# R40 register map
Vendor: Allwinner; Series: R40; File version: 0.1
CPU: CA7 0, little endian, MPU, FPU, double-precision FPU, 0 interrupt priority bits
Registers are 32-bit, read-write, reset 0x0 unless marked. A register's access mark holds for its fields unless they carry their own. Offsets are from the block's base; [hi:lo] are bit positions; {n}, {i} and the like mark numbered series; 'fields as' and 'values as' point back to an identical list; <NAME> marks a mode.

## Audio_Codec
Base 0x01C22C00
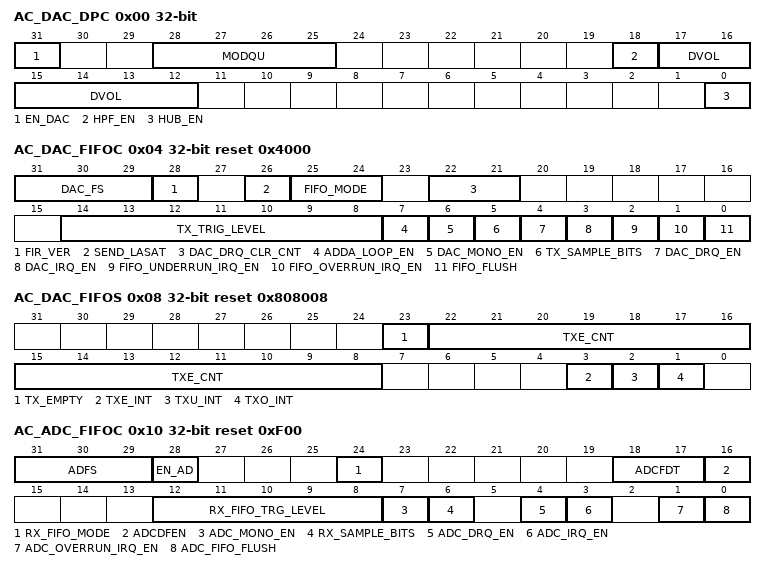
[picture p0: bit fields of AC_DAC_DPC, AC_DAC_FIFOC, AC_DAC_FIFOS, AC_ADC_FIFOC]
0x00 AC_DAC_DPC — DAC Digital Part Control Register
  [31] EN_DAC — DAC Digital Part Enable 0 : Disable 1 : Enable
  [28:25] MODQU — Internal DAC Quantization Levels Levels=[7*(21+MODQU[3:0])]/128 Default levels=7*21/128=1.15
  [18] HPF_EN — High Pass Filter Enable 0: Disable 1: Enable
    0=Disable; 1=Enable
  [17:12] DVOL — Digital Volume Control DVC, ATT=DVC[5:0]*(-1.16Db) 64 steps, -1.16Db/step
  [0] HUB_EN — Audio Hub Enable 0:Disable 1:Enable
0x04 AC_DAC_FIFOC reset 0x4000 — DAC FIFO Control Register
  [31:29] DAC_FS — Sample Rate Of DAC 000: 48KHz 010: 24KHz 100: 12KHz 110: 192KHz 001: 32KHz 011: 16KHz 101: 8KHz 111: 96KHz 44.1KHz/22.05KHz/11.025KHz can be supported by Audio PLL Configure Bit
    0=_48KHz; 2=_24KHz; 4=_12KHz; 6=_192KHz; 1=_32KHz; 3=_16KHz; 5=_8KHz; 7=96KHz 44.1KHz/22.05KHz/11.025KHz can be supported by Audio PLL Configure Bit
  [28] FIR_VER — FIR Version 0: 64-Tap FIR 1: 32-Tap FIR
    0=_64_minus_Tap (64-Tap FIR); 1=_32_minus_Tap (32-Tap FIR)
  [26] SEND_LASAT — Audio sample select when TX FIFO under run 0: Sending zero 1: Sending last audio sample
    0=Sending_zero; 1=Sending last audio sample
  [25:24] FIFO_MODE — For 24-bits transmitted audio sample 00/10: FIFO_I[23:0] = {TXDATA[31:8]} 01/11: Reserved For 16-bits transmitted audio sample: 00/10: FIFO_I*23:0+ = ,TXDATA*31:16+, 8`b0- 01/11: FIFO_I*23:0+ = ,TXDATA*15:0+, 8`b0-
  [22:21] DAC_DRQ_CLR_CNT — When TX FIFO Available Room Less Than Or Equal N, DRQ Request Will Be De-Asserted. N Is Defined Here: 00: IRQ/DRQ De-Asserted When WLEVEL > TXTL 01: 4 10: 8 11: 16
    0=IRQ_slash_DRQ (IRQ/DRQ De-Asserted When WLEVEL > TXTL); 1=_4; 2=_8; 3=_16
  [14:8] TX_TRIG_LEVEL — TX FIFO Empty Trigger Level (TXTL[12:0]) Interrupt and DMA request trigger level for TX FIFO normal condition. IRQ/DRQ Generated when WLEVEL <= TXTL Notes: 1. WLEVEL represents the number of valid samples in the TX FIFO 2. Only TXTL[6:0] valid when TXMODE = 0
  [7] ADDA_LOOP_EN — ADDA Loop Enable 0: Disable 1: Enable
    0=Disable; 1=Enable
  [6] DAC_MONO_EN — DAC Mono Enable 0: Stereo, 64 Levels FIFO 1: Mono, 128 Levels FIFO When Enabled, L & R Channel Send Same Data
    0=Stereo, 64 Levels FIFO; 1=Mono, 128 Levels FIFO When Enabled, L & R Channel Send Same Data
  [5] TX_SAMPLE_BITS — Transmitting Audio Sample Resolution 0: 16 bits 1: 24 bits
    0=_16_bits; 1=_24_bits
  [4] DAC_DRQ_EN — DAC FIFO Empty DRQ Enable 0: Disable 1: Enable
    0=Disable; 1=Enable
  [3] DAC_IRQ_EN — DAC FIFO Empty IRQ Enable 0: Disable 1: Enable
    0=Disable; 1=Enable
  [2] FIFO_UNDERRUN_IRQ_EN — DAC FIFO Under Run IRQ Enable 0: Disable 1: Enable
    0=Disable; 1=Enable
  [1] FIFO_OVERRUN_IRQ_EN — DAC FIFO Over Run IRQ Enable 0: Disable 1: Enable
    0=Disable; 1=Enable
  [0] FIFO_FLUSH write-1-clears — DAC FIFO Flush Write `1` to flush TX FIFO, Self clear to `0`
0x08 AC_DAC_FIFOS reset 0x808008 — DAC FIFO Status Register
  [23] TX_EMPTY ro — TX FIFO Empty 0: No room for new sample in TX FIFO 1: More than one room for new sample in TX FIFO (>= 1 word)
    0=No room for new sample in TX FIFO; 1=More than one room for new sample in TX FIFO (>= 1 word)
  [22:8] TXE_CNT ro — TX FIFO Empty Space Word Counter
  [3] TXE_INT write-1-clears — TX FIFO Empty Pending Interrupt 0: No Pending IRQ 1: FIFO Empty Pending Interrupt Write `1` to clear this interrupt or automatically clear if interrupt condition fails
    0=No Pending IRQ; 1=FIFO (FIFO Empty Pending Interrupt Write `1` to clear this interrupt or automatically clear if interrupt condition fails)
  [2] TXU_INT write-1-clears — TX FIFO Under run Pending Interrupt 0: No Pending Interrupt 1: FIFO Under run Pending Interrupt Write `1` to clear this interrupt
    0=No Pending Interrupt; 1=FIFO (FIFO Under run Pending Interrupt Write `1` to clear this interrupt)
  [1] TXO_INT write-1-clears — TX FIFO Overrun Pending Interrupt 0: No Pending Interrupt 1: FIFO Overrun Pending Interrupt Write `1` to clear this interrupt
    0=No Pending Interrupt; 1=FIFO (FIFO Overrun Pending Interrupt Write `1` to clear this interrupt)
0x10 AC_ADC_FIFOC reset 0xF00 — ADC FIFO Control Register
  [31:29] ADFS — Sample Rate of ADC 000: 48KHz 010: 24KHz 100: 12KHz 110: Reserved 001: 32KHz 011: 16KHz 101: 8KHz 111: Reserved 44.1KHz/22.05KHz/11.025KHz can be supported by Audio PLL Configure Bit
    0=_48KHz; 2=_24KHz; 4=_12KHz; 1=_32KHz; 3=_16KHz; 5=_8KHz
  [28] EN_AD — ADC Digital Part Enable 0: Disable 1: Enable
    0=Disable; 1=Enable
  [24] RX_FIFO_MODE — RX FIFO Output Mode (Mode 0, 1) 0: Expanding `0` at LSB of TX FIFO register 1: Expanding received sample sign bit at MSB of TX FIFO register For 24-bits received audio sample: Mode 0: RXDATA[31:0+ = ,FIFO_O*23:0+, 8`h0- Mode 1: Reserved For 16-bits received audio sample: Mode 0: RXDATA*31:0+ = ,FIFO_O*23:8+, 16`h0- Mode 1: RXDATA[31:0] = {16{FIFO_O[23]}, FIFO_O[23:8]}
    0=Expanding `0` at LSB of TX FIFO register; 1=Expanding received sample sign bit at MSB of TX FIFO register For 24-bits received audio sample: Mode 0: RXDATA[31:0+ = ,FIFO_O*23:0+, 8`h0- Mode 1: Reserved For 16-bits received audio sample: Mode 0: RXDATA*31:0+ = ,FIFO_O*23:8+, 16`h0- Mode 1: RXDATA[31:0] = {16{FIFO_O[23]}, FIFO_O[23:8]}
  [18:17] ADCFDT — ADC FIFO Delay Time for writing Data after EN_AD 00:5ms 01:10ms 10:20ms 11:30ms
  [16] ADCDFEN — ADC FIFO Delay Function for writing Data after EN_AD 0: Disable 1: Enable
    0=Disable; 1=Enable
  [12:8] RX_FIFO_TRG_LEVEL — RX FIFO Trigger Level (RXTL[4:0]) Interrupt and DMA request trigger level for RX FIFO normal condition IRQ/DRQ Generated when WLEVEL > RXTL[4:0] Notes: WLEVEL represents the number of valid samples in the RX FIFO
  [7] ADC_MONO_EN — ADC Mono Enable 0: Stereo, 16 levels FIFO 1: mono, 32 levels FIFO When set to `1`, Only left channel samples are recorded
    0=Stereo, 16 levels FIFO; 1=mono, 32 levels FIFO When set to `1`, Only left channel samples are recorded
  [6] RX_SAMPLE_BITS — Receiving Audio Sample Resolution 0: 16 bit 1: 24 bit
    0=_16_bit; 1=_24_bit
  [4] ADC_DRQ_EN — ADC FIFO Data Available DRQ Enable 0: Disable 1: Enable
    0=Disable; 1=Enable
  [3] ADC_IRQ_EN — ADC FIFO Data Available IRQ Enable 0: Disable 1: Enable
    0=Disable; 1=Enable
  [1] ADC_OVERRUN_IRQ_EN — ADC FIFO Over Run IRQ Enable 0: Disable 1: Enable
    0=Disable; 1=Enable
  [0] ADC_FIFO_FLUSH write-1-clears — ADC FIFO Flush Write `1` to flush TX FIFO, self clear to `0`
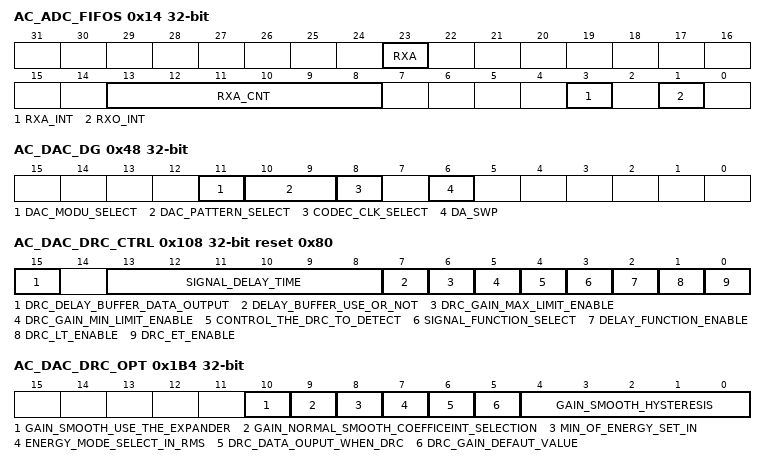
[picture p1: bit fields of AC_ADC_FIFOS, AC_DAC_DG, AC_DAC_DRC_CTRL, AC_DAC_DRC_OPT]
0x14 AC_ADC_FIFOS — ADC FIFO Status Register
  [23] RXA ro — RX FIFO Available 0: No available data in RX FIFO 1: More than one sample in RX FIFO (>= 1 word)
    0=No available data in RX FIFO; 1=More than one sample in RX FIFO (>= 1 word)
  [13:8] RXA_CNT ro — RX FIFO Available Sample Word Counter
  [3] RXA_INT write-1-clears — RX FIFO Data Available Pending Interrupt 0: No Pending IRQ 1: Data Available Pending IRQ Write `1` to clear this interrupt or automatically clear if interrupt condition fails
    0=No Pending IRQ; 1=Data Available Pending IRQ Write `1` to clear this interrupt or automatically clear if interrupt condition fails
  [1] RXO_INT write-1-clears — RX FIFO Overrun Pending Interrupt 0: No Pending IRQ 1: FIFO Overrun Pending IRQ Write `1` to clear this interrupt
    0=No Pending IRQ; 1=FIFO (FIFO Overrun Pending IRQ Write `1` to clear this interrupt)
0x18 AC_ADC_RXDATA — ADC RX Data Register
  [31:0] RX_DATA ro — RX Sample Host can get one sample by reading this register. The left channel sample data is first and then the right channel sample.
0x20 AC_DAC_TXDATA — DAC TX Data Register
  [31:0] TX_DATA wo — Transmitting left, right channel sample data should be written this register one by one. The left channel sample data is first and then the right channel sample.
0x40 AC_DAC_CNT — DAC TX FIFO Counter Register
  [31:0] TX_CNT — TX Sample Counter The audio sample number of sending into TXFIFO. When one sample is put into TXFIFO by DMA or by host IO, the TX sample counter register increases by one. The TX sample counter register can be set to any initial valve at any time. After been updated by the initial value, the counter register should count on base of this initial value. Note: It is used for Audio/ Video Synchronization
0x44 AC_ADC_CNT — ADC RX FIFO Counter Register
  [31:0] RX_CNT — RX Sample Counter The audio sample number of writing into RXFIFO. When one sample is written by Digital Audio Engine, the RX sample counter register increases by one. The RX sample counter register can be set to any initial valve at any time. After been updated by the initial value, the counter register should count on base of this initial value Note: It is used for Audio/ Video Synchronization
0x48 AC_DAC_DG — DAC Debug Register
  [11] DAC_MODU_SELECT — DAC Modulator Debug 0: DAC Modulator Normal Mode 1: DAC Modulator Debug Mode
    0=DAC Modulator Normal Mode; 1=DAC Modulator Debug Mode
  [10:9] DAC_PATTERN_SELECT — DAC Pattern Select 00: Normal (Audio Sample from TX FIFO) 01: -6 dB Sin wave 10: -60 dB Sin wave 11: Silent wave
    0=Normal (Audio Sample from TX FIFO); 1=_minus_6_dB (-6 dB Sin wave); 2=_minus_60_dB (-60 dB Sin wave); 3=Silent wave
  [8] CODEC_CLK_SELECT — CODEC Clock Source Select 0: CODEC Clock from PLL 1: CODEC Clock from OSC (for Debug)
    0=CODEC_Clock_from_PLL; 1=CODEC Clock from OSC (for Debug)
  [6] DA_SWP — DAC output channel swap enable 0: Disable 1: Enable
    0=Disable; 1=Enable
0x4C AC_ADC_DG — ADC Debug Register
  [24] AD_SWP — ADC Output Channel Swap Enable (for digital filter) 0: Disable 1: Enable
    0=Disable; 1=Enable
0x100 AC_DAC_DRC_HHPFC reset 0xFF — DAC DRC High HPF Coef Register
  [10:0] HPF — coefficient setting and the data is 3.24 format.
0x104 AC_DAC_DRC_LHPFC reset 0xFAC1 — DAC DRC Low HPF Coef Register
  [15:0] HPF — coefficient setting and the data is 3.24 format.
0x108 AC_DAC_DRC_CTRL reset 0x80 — DAC DRC Control Register
  [15] DRC_DELAY_BUFFER_DATA_OUTPUT ro — DRC delay buffer data output state when drc delay function is enble and the drc funciton disable. After disable drc function and this bit go to 0, the user should write the drc delay function bit to 0. 0 : Not complete 1 : Complete
  [13:8] SIGNAL_DELAY_TIME — Signal delay time setting 6'h00 : (8x1)fs 6'h01 : (8x2)fs 6'h02 : (8x3)fs ---------------------------------------- 6'h2e : (8*47)fs 6'h2f : (8*48)fs 6'h30 -- 6'h3f : (8*48)fs Delay time = 8*(n+1)fs, n<6'h30; When the delay function is disable, the signal delay time is unused.
  [7] DELAY_BUFFER_USE_OR_NOT — The delay buffer use or not when the drc disable and the drc buffer data output completely 0 : Don't use the buffer 1 : Use the buffer
  [6] DRC_GAIN_MAX_LIMIT_ENABLE — DRC gain max limit enable 0 : Disable 1 : Enable
  [5] DRC_GAIN_MIN_LIMIT_ENABLE — DRC gain min limit enable. when this fuction enable, it will overwrite the noise detect funciton. 0 : Disable 1 : Enable
  [4] CONTROL_THE_DRC_TO_DETECT — Control the drc to detect noise when ET enable 0 : Disable 1 : Enable
  [3] SIGNAL_FUNCTION_SELECT — Signal function Select 0 : RMS filter 1 : Peak filter When Signal function Select Peak filter, the RMS parameter is unused. (AC_DRC_LRMSHAT / AC_DRC_LRMSLAT / AC_DRC_LRMSHAT / AC_DRC_LRMSLAT) When Signal function Select RMS filter, the Peak filter parameter is unused.(AC_DRC_LPFHAT / AC_DRC_LPFLAT / AC_DRC_RPFHAT / AC_DRC_RPFLAT / AC_DRC_LPFHRT / AC_DRC_LPFLRT / AC_DRC_RPFHRT / AC_DRC_RPFLRT)
  [2] DELAY_FUNCTION_ENABLE — Delay function enable 0 : Disable 1 : Enable When the Delay function enable is disabled, the Signal delay time is unused.
  [1] DRC_LT_ENABLE — DRC LT enable 0 : Disable 1 : Enable When the DRC LT is disabled the LT, Kl and OPL parameter is unused.
  [0] DRC_ET_ENABLE — DRC ET enable 0 : Disable 1 : Enable When the DRC ET is disabled the ET, Ke and OPE parameter is unused.
0x10C AC_DAC_DRC_LPFHAT reset 0xB — DAC DRC Left Peak Filter High Attack Time Coef Register
  [10:0] LEFT_PEAK_FILTER_ATTACK_TIME — The left peak filter attack time parameter setting, which determine by the equation that AT = 1-exp(-2.2Ts/ta). The format is 3.24. (1ms)
0x110 AC_DAC_DRC_LPFLAT reset 0x77BF — DAC DRC Left Peak Filter Low Attack Time Coef Register
  [15:0] LEFT_PEAK_FILTER_ATTACK_TIME — The left peak filter attack time parameter setting, which determine by the equation that AT = 1-exp(-2.2Ts/ta). The format is 3.24. (1ms)
0x114 AC_DAC_DRC_RPFHAT reset 0xB — DAC DRC Right Peak Filter High Attack Time Coef Register
  fields as AC_DAC_DRC_LPFHAT
0x118 AC_DAC_DRC_RPFLAT reset 0x77BF — DAC DRC Peak Filter Low Attack Time Coef Register
  fields as AC_DAC_DRC_LPFLAT
0x11C AC_DAC_DRC_LPFHRT reset 0xFF — DAC DRC Left Peak Filter High Release Time Coef Register
  [10:0] LEFT_PEAK_FILTER_RELEASE_TIME — The left peak filter release time parameter setting, which determine by the equation that RT = exp(-2.2Ts/tr). The format is 3.24. (100ms)
0x120 AC_DAC_DRC_LPFLRT reset 0xE1F8 — DAC DRC Left Peak Filter Low Release Time Coef Register
  [15:0] LEFT_PEAK_FILTER_RELEASE_TIME — The left peak filter release time parameter setting, which determine by the equation that RT = exp(-2.2Ts/tr). The format is 3.24. (100ms)
0x124 AC_DAC_DRC_RPFHRT reset 0xFF — DAC DRC Right Peak Filter High Release Time Coef Register
  [10:0] LEFT_PEAK_FILTER_ATTACK_TIME — The left peak filter attack time parameter setting, which determine by the equation that RT = exp(-2.2Ts/tr). The format is 3.24. (100ms)
0x128 AC_DAC_DRC_RPFLRT reset 0xE1F8 — DAC DRC Right Peak Filter Low Release Time Coef Register
  [15:0] LEFT_PEAK_FILTER_RELEASE_TIME — The left peak filter release time parameter setting, which determine by the equation that AT = exp(-2.2Ts/tr). The format is 3.24. (100ms)
0x12C AC_DAC_DRC_LRMSHAT reset 0x1 — DAC DRC Left RMS Filter High Coef Register
  [10:0] LEFT_RMS_FILTER_AVERAGE_TIME — The left RMS filter average time parameter setting, which determine by the equation that AT = 1-exp(-2.2Ts/tav). The format is 3.24. (10ms)
0x130 AC_DAC_DRC_LRMSLAT reset 0x2BAF — DAC DRC Left RMS Filter Low Coef Register
  [15:0] LEFT_RMS_FILTER_AVERAGE_TIME — The left RMS filter average time parameter setting, which determine by the equation that AT = 1-exp(-2.2Ts/tav). The format is 3.24. (10ms)
0x134 AC_DAC_DRC_RRMSHAT reset 0x1 — DAC DRC Right RMS Filter High Coef Register
  [10:0] RIGHT_RMS_FILTER_AVERAGE_TIME — The right RMS filter average time parameter setting, which determine by the equation that AT = 1-exp(-2.2Ts/tav). The format is 3.24. (10ms)
0x138 AC_DAC_DRC_RRMSLAT reset 0x2BAF — DAC DRC Right RMS Filter Low Coef Register
  [15:0] RIGHT_RMS_FILTER_AVERAGE_TIME — The right RMS filter average time parameter setting, which determine by the equation that AT = 1-exp(-2.2Ts/tav). The format is 3.24. (10ms)
0x13C AC_DAC_DRC_HCT reset 0x6A4 — DAC DRC Compressor Theshold High Setting Register
  [15:0] COMPRESSOR_THRESHOLD — The compressor threshold setting, which set by the equation that CTin = -CT/6.0206. The format is 8.24 (-40dB)
0x140 AC_DAC_DRC_LCT reset 0xD3C0 — DAC DRC Compressor Slope High Setting Register
  fields as AC_DAC_DRC_HCT
0x144 AC_DAC_DRC_HKC reset 0x80 — DAC DRC Compressor Slope High Setting Register
  [13:0] COMPRESSOR_SLOPE — The slope of the compressor which determine by the equation that Kc = 1/R, there, R is the ratio of the compressor, which always is interger. The format is 6.24. (2 : 1)
0x148 AC_DAC_DRC_LKC — DAC DRC Compressor Slope Low Setting Register
  [15:0] COMPRESSOR_SLOPE — The slope of the compressor which determine by the equation that Kc = 1/R, there, R is the ratio of the compressor, which always is interger. The format is 6.24. (2 : 1)
0x14C AC_DAC_DRC_HOPC reset 0xF95B — DAC DRC Compressor High Output at Compressor Threshold Register
  [15:0] COMPRESSOR_OUTPUT — The output of the compressor which determine by the equation -OPC/6.0206 The format is 8.24 (-40dB)
0x150 AC_DAC_DRC_LOPC reset 0x2C3F — DAC DRC Compressor Low Output at Compressor Threshold Register
  [15:0] COMPRESSOR_OUTPUT — The output of the compressor which determine by the equation OPC/6.0206 The format is 8.24 (-40dB)
0x154 AC_DAC_DRC_HLT reset 0x1A9 — DAC DRC Limiter Theshold High Setting Register
  [15:0] LIMITER_THRESHOLD — The limiter threshold setting, which set by the equation that LTin = -LT/6.0206, The format is 8.24. (-10dB)
0x158 AC_DAC_DRC_LLT reset 0x34F0 — DAC DRC Limiter Theshold Low Setting Register
  fields as AC_DAC_DRC_HLT
0x15C AC_DAC_DRC_HKl reset 0x5 — DAC DRC Limiter Slope High Setting Register
  [13:0] LIMITER_SLOPE — The slope of the limiter which determine by the equation that Kl = 1/R, R is the ratio of the limiter, which always is interger. The format is 6.24. (50 :1)
0x160 AC_DAC_DRC_LKl reset 0x1EB8 — DAC DRC Limiter Slope Low Setting Register
  [15:0] LIMITER_SLOPE — The slope of the limiter which determine by the equation that Kl = 1/R, there, R is the ratio of the limiter, which always is interger. The format is 6.24. (50 :1)
0x164 AC_DAC_DRC_HOPL reset 0xFBD8 — DAC DRC Limiter High Output at Limiter Threshold
  [15:0] LIMITER_OUTPUT — The output of the limiter which determine by equation OPT/6.0206. The format is 8.24 (-25dB)
0x168 AC_DAC_DRC_LOPL reset 0xFBA7 — DAC DRC Limiter Low Output at Limiter Threshold
  fields as AC_DAC_DRC_HOPL
0x16C AC_DAC_DRC_HET reset 0xBA0 — DAC DRC Expander Theshold High Setting Register
  [15:0] EXPANDER_THRESHOLD — The expander threshold setting, which set by the equation that ETin = -ET/6.0206, The format is 8.24. (-70dB)
0x170 AC_DAC_DRC_LET reset 0x7291 — DAC DRC Expander Theshold Low Setting Register
  fields as AC_DAC_DRC_HET
0x174 AC_DAC_DRC_HKE reset 0x500 — DAC DRC Expander Slope High Setting Register
  [13:0] EXPANDER_SLOPE — The slope of the expander which determine by the equation that Ke = 1/R, there, R is the ratio of the expander, which always is interger and the ke must larger than 1/50. The format is 6.24. (1:5)
0x178 AC_DAC_DRC_LKE — DAC DRC Expander Slope Low Setting Register
  [15:0] EXPANDER_SLOPE — The slope of the expander which determine by the equation that Ke = 1/R, there, R is the ratio of the expander, which always is interger and the ke must larger than 1/50. The format is 6.24. (1:5)
0x17C AC_DAC_DRC_HOPE reset 0xF45F — DAC DRC Expander High Output at Expander Threshold
  [15:0] EXPANDER_OUTPUT — The output of the expander which determine by equation OPE/6.0206. The format is 8.24 (-70dB)
0x180 AC_DAC_DRC_LOPE reset 0x8D6E — DAC DRC Expander Low Output at Expander Threshold
  fields as AC_DAC_DRC_HOPE
0x184 AC_DAC_DRC_HKN reset 0x100 — DAC DRC Linear Slope High Setting Register
  [13:0] LINEAR_SLOPE — The slope of the linear which determine by the equation that Kn = 1/R, there, R is the ratio of the linear, which always is interger . The format is 6.24. (1:1)
0x188 AC_DAC_DRC_LKN — DAC DRC Linear Slope Low Setting Register
  [15:0] LINEAR_SLOPE — The slope of the linear which determine by the equation that Kn = 1/R, there, R is the ratio of the linear, which always is interger . The format is 6.24. (1:1)
0x18C AC_DAC_DRC_SFHAT reset 0x2 — DAC DRC Smooth Filter Gain High Attack Time Coef Register
  [10:0] SMOOTH_FILTER_ATTACK_TIME — The smooth filter attack time parameter setting, which determine by the equation that AT = 1-exp(-2.2Ts/tr). The format is 3.24. (5ms)
0x190 AC_DAC_DRC_SFLAT reset 0x5600 — DAC DRC Smooth Filter Gain Low Attack Time Coef Register
  [15:0] SMOOTH_FILTER_ATTACK_TIME — The smooth filter attack time parameter setting, which determine by the equation that AT = 1-exp(-2.2Ts/tr). The format is 3.24. (5ms)
0x194 AC_DAC_DRC_SFHRT — DAC DRC Smooth Filter Gain High Release Time Coef Register
  [10:0] GAIN_SMOOTH_FILTER_RELEASE_TIME — The gain smooth filter release time parameter setting, which determine by the equation that RT = 1-exp(-2.2Ts/tr). The format is 3.24. (200ms)
0x198 AC_DAC_DRC_SFLRT reset 0xF04 — DAC DRC Smooth Filter Gain Low Release Time Coef Register
  [15:0] GAIN_SMOOTH_FILTER_RELEASE_TIME — The gain smooth filter release time parameter setting, which determine by the equation that RT = 1-exp(-2.2Ts/tr). The format is 3.24. (200ms)
0x19C AC_DAC_DRC_MXGHS reset 0xFE56 — DAC DRC MAX Gain High Setting Register
  [15:0] MAX_GAIN — The max gain setting which determine by equation MXG/6.0206. The format is 8.24 and must -20dB <MXG< 30dB (-10dB)
0x1A0 AC_DAC_DRC_MXGLS reset 0xCB0F — DAC DRC MAX Gain Low Setting Register
  [15:0] MAX_GAIN — The max gain setting which determine by equation MXG/6.0206. The format is 8.24 and must -20dB <MXG < 30dB (-10dB)
0x1A4 AC_DAC_DRC_MNGHS reset 0xF95B — DAC DRC MIN Gain High Setting Register
  [15:0] MIN_GAIN — The min gain setting which determine by equation MXG/6.0206. The format is 8.24 and must -60dB <=MNG <= -40dB (-40dB)
0x1A8 AC_DAC_DRC_MNGLS reset 0x2C3F — DAC DRC MIN Gain Low Setting Register
  [15:0] MIN_GAIN — The min gain setting which determine by equation MNG/6.0206. The format is 8.24 and must -60dB <=MNG <= -40dB (-40dB)
0x1AC AC_DAC_DRC_EPSHC — DAC DRC Expander Smooth Time High Coef Register
  [11:0] GAIN_SMOOTH_FILTER_RELEASE — The gain smooth filter release and attack time parameter setting in expander region, which determine by the equation that RT = 1-exp(-2.2Ts/tr). The format is 3.24. (30ms)
0x1B0 AC_DAC_DRC_EPSLC reset 0x640C — DAC DRC Expander Smooth Time Low Coef Register
  [15:0] GAIN_SMOOTH_FILTER_RELEASE — The gain smooth filter release and attack time parameter setting in expander region, which determine by the equation that RT = 1-exp(-2.2Ts/tr). The format is 3.24. (30ms)
0x1B4 AC_DAC_DRC_OPT — DAC DRC Optimum Register
  [10] GAIN_SMOOTH_USE_THE_EXPANDER — The gain smooth use the expander coiffcient when the energy in expander range 0 : use the normal smooth coeffcient 1 : use the expander coeffcient
  [9] GAIN_NORMAL_SMOOTH_COEFFICEINT_SELECTION — The gain normal smooth coefficeint selection mode set 0 : both release and attack coeffcient use hysteresis 1 : only the attack coeffcient use hysteresis
  [8] MIN_OF_ENERGY_SET_IN — The min of energy set in Peak detect mode 0 : -120dB 1 : -210dB
  [7] ENERGY_MODE_SELECT_IN_RMS — The energy mode select in rms detect mode 0 : the energy is RMS 1 : the energy is square of RMS
  [6] DRC_DATA_OUPUT_WHEN_DRC — DRC data ouput when DRC disable and DRC delay data output complete 0 : the ouput is the input music data; 1 : the output is 0
  [5] DRC_GAIN_DEFAUT_VALUE — DRC gain defaut value setting 0: The default gain is 1 1: The default gain is 0
    0=The default gain is 1; 1=The default gain is 0
  [4:0] GAIN_SMOOTH_HYSTERESIS — The hysteresis of the gain smooth filter to use the decay time coefficient or the attack time coefficient. When in the decay time state, if g(n-1)-g(n)>hysteresis, then the state will change to attack time state, and when in the attack time, if g(n)-g(n-1)>hysteresis, then the state will change to decay time state. Note the hysteresis of 0x00 and 0x04 is the same. 00000: 2^(-20) 00001: 2^(-19) 00010: 2^(-18) ----------------- 10011: 2^(-1) 10100 ~11111: 1 hysteresis = 2^(n-20) ,except n=0x00, and n less 0x14.
    0=_2_circumflex__openingparen__minus_20_closingparen_ (2^(-20)); 1=_2_circumflex__openingparen__minus_19_closingparen_ (2^(-19)); 2=_2_circumflex__openingparen__minus_18_closingparen_ (2^(-18) -----------------); 19=_2_circumflex__openingparen__minus_1_closingparen_ (2^(-1) 10100 ~11111: 1 hysteresis = 2^(n-20) ,except n=0x00, and n less 0x14.)
0x200 AC_ADC_DRC_HHPFC reset 0xFF — ADC DRC High HPF Coef Register
  [10:0] HPF — coefficient setting and the data is 3.24 format.
0x204 AC_ADC_DRC_LHPFC reset 0xFAC1 — ADC DRC Low HPF Coef Register
  [15:0] HPF — coefficient setting and the data is 3.24 format.
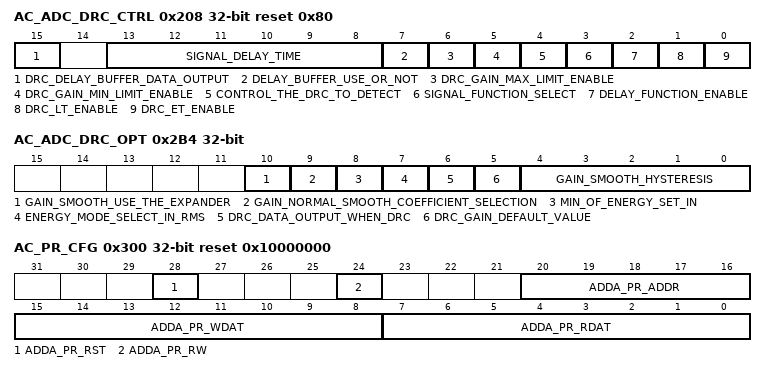
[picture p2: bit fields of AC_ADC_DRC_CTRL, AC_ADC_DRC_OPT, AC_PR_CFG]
0x208 AC_ADC_DRC_CTRL reset 0x80 — ADC DRC Control Register
  [15] DRC_DELAY_BUFFER_DATA_OUTPUT ro — DRC delay buffer data output state when drc delay function is enble and the drc funciton disable. After disable drc function and this bit go to 0, the user should write the drc delay function bit to 0 0 : Not complete 1 : Complete
  [13:8] SIGNAL_DELAY_TIME — Signal delay time setting 6'h00 : (8x1)fs 6'h01 : (8x2)fs 6'h02 : (8x3)fs ---------------------------------------- 6'h2e : (8*47)fs 6'h2f : (8*48)fs 6'h30 -- 6'h3f : (8*48)fs Delay time = 8*(n+1)fs, n<6'h30; When the delay function is disable, the signal delay time is unused.
  [7] DELAY_BUFFER_USE_OR_NOT — The delay buffer use or not when the drc disable and the drc buffer data output completely 0 : Don't use the buffer 1 : Use the buffer
  [6] DRC_GAIN_MAX_LIMIT_ENABLE — DRC gain max limit enable 0 : Disable 1 : Enable
  [5] DRC_GAIN_MIN_LIMIT_ENABLE — DRC gain min limit enable. when this fuction enable, it will overwrite the noise detect function 0 : Disable 1 : Enable
  [4] CONTROL_THE_DRC_TO_DETECT — Control the drc to detect noise when ET enable 0 : Disable 1 : Enable
  [3] SIGNAL_FUNCTION_SELECT — Signal function Select 0 : RMS filter 1 : Peak filter When Signal function Select Peak filter, the RMS parameter is unused. (AC_DRC_LRMSHAT / AC_DRC_LRMSLAT / AC_DRC_LRMSHAT / AC_DRC_LRMSLAT) When Signal function Select RMS filter, the Peak filter parameter is unused.(AC_DRC_LPFHAT / AC_DRC_LPFLAT / AC_DRC_RPFHAT / AC_DRC_RPFLAT / AC_DRC_LPFHRT / AC_DRC_LPFLRT / AC_DRC_RPFHRT / AC_DRC_RPFLRT)
  [2] DELAY_FUNCTION_ENABLE — Delay function enable 0 : Disable 1 : Enable When the bit is disabled, the signal delay time is unused.
  [1] DRC_LT_ENABLE — DRC LT enable 0 : Disable 1 : Enable When the DRC LT is disabled the LT, Kl and OPL parameter is unused.
  [0] DRC_ET_ENABLE — DRC ET enable 0 : Disable 1 : Enable When the DRC ET is disabled the ET, Ke and OPE parameter is unused.
0x20C AC_ADC_DRC_LPFHAT reset 0xB — ADC DRC Left Peak Filter High Attack Time Coef Register
  fields as AC_DAC_DRC_LPFHAT
0x210 AC_ADC_DRC_LPFLAT reset 0x77BF — ADC DRC Left Peak Filter Low Attack Time Coef Register
  fields as AC_DAC_DRC_LPFLAT
0x214 AC_ADC_DRC_RPFHAT reset 0xB — ADC DRC Right Peak Filter High Attack Time Coef Register
  fields as AC_DAC_DRC_LPFHAT
0x218 AC_ADC_DRC_RPFLAT reset 0x77BF — ADC DRC Peak Filter Low Attack Time Coef Register
  fields as AC_DAC_DRC_LPFLAT
0x21C AC_ADC_DRC_LPFHRT reset 0xFF — ADC DRC Left Peak Filter High Release Time Coef Register
  fields as AC_DAC_DRC_LPFHRT
0x220 AC_ADC_DRC_LPFLRT reset 0xE1F8 — ADC DRC Left Peak Filter Low Release Time Coef Register
  fields as AC_DAC_DRC_LPFLRT
0x224 AC_ADC_DRC_RPFHRT reset 0xFF — ADC DRC Right Peak Filter High Release Time Coef Register
  fields as AC_DAC_DRC_RPFHRT
0x228 AC_ADC_DRC_RPFLRT reset 0xE1F8 — ADC DRC Right Peak Filter Low Release Time Coef Register
  fields as AC_DAC_DRC_RPFLRT
0x22C AC_ADC_DRC_LRMSHAT reset 0x1 — ADC DRC Left RMS Filter High Coef Register
  fields as AC_DAC_DRC_LRMSHAT
0x230 AC_ADC_DRC_LRMSLAT reset 0x2BAF — ADC DRC Left RMS Filter Low Coef Register
  fields as AC_DAC_DRC_LRMSLAT
0x234 AC_ADC_DRC_RRMSHAT reset 0x1 — ADC DRC Right RMS Filter High Coef Register
  fields as AC_DAC_DRC_RRMSHAT
0x238 AC_ADC_DRC_RRMSLAT reset 0x2BAF — ADC DRC Right RMS Filter Low Coef Register
  fields as AC_DAC_DRC_RRMSLAT
0x23C AC_ADC_DRC_HCT reset 0x6A4 — ADC DRC Compressor Theshold High Setting Register
  fields as AC_DAC_DRC_HCT
0x240 AC_ADC_DRC_LCT reset 0xD3C0 — ADC DRC Compressor Slope High Setting Register
  fields as AC_DAC_DRC_HCT
0x244 AC_ADC_DRC_HKC reset 0x80 — ADC DRC Compressor Slope High Setting Register
  fields as AC_DAC_DRC_HKC
0x248 AC_ADC_DRC_LKC — ADC DRC Compressor Slope Low Setting Register
  fields as AC_DAC_DRC_LKC
0x24C AC_ADC_DRC_HOPC reset 0xF95B — ADC DRC Compressor High Output at Compressor Threshold Register
  fields as AC_DAC_DRC_HOPC
0x250 AC_ADC_DRC_LOPC reset 0x2C3F — ADC DRC Compressor Low Output at Compressor Threshold Register
  fields as AC_DAC_DRC_LOPC
0x254 AC_ADC_DRC_HLT reset 0x1A9 — ADC DRC Limiter Theshold High Setting Register
  fields as AC_DAC_DRC_HLT
0x258 AC_ADC_DRC_LLT reset 0x34F0 — ADC DRC Limiter Theshold Low Setting Register
  fields as AC_DAC_DRC_HLT
0x25C AC_ADC_DRC_HKl reset 0x5 — ADC DRC Limiter Slope High Setting Register
  [13:0] LIMITER_SLOPE — The slope of the limiter which determine by the equation that Kl = 1/R, there, R is the ratio of the limiter, which always is interger. The format is 6.24. (50 :1)
0x260 AC_ADC_DRC_LKl reset 0x1EB8 — ADC DRC Limiter Slope Low Setting Register
  fields as AC_DAC_DRC_LKl
0x264 AC_ADC_DRC_HOPL reset 0xFBD8 — ADC DRC Limiter High Output at Limiter Threshold
  fields as AC_DAC_DRC_HOPL
0x268 AC_ADC_DRC_LOPL reset 0xFBA7 — ADC DRC Limiter Low Output at Limiter Threshold
  fields as AC_DAC_DRC_HOPL
0x26C AC_ADC_DRC_HET reset 0xBA0 — ADC DRC Expander Theshold High Setting Register
  fields as AC_DAC_DRC_HET
0x270 AC_ADC_DRC_LET reset 0x7291 — ADC DRC Expander Theshold Low Setting Register
  fields as AC_DAC_DRC_HET
0x274 AC_ADC_DRC_HKE reset 0x500 — ADC DRC Expander Slope High Setting Register
  fields as AC_DAC_DRC_HKE
0x278 AC_ADC_DRC_LKE — ADC DRC Expander Slope Low Setting Register
  fields as AC_DAC_DRC_LKE
0x27C AC_ADC_DRC_HOPE reset 0xF45F — ADC DRC Expander High Output at Expander Threshold
  fields as AC_DAC_DRC_HOPE
0x280 AC_ADC_DRC_LOPE reset 0x8D6E — ADC DRC Expander Low Output at Expander Threshold
  fields as AC_DAC_DRC_HOPE
0x284 AC_ADC_DRC_HKN reset 0x100 — ADC DRC Linear Slope High Setting Register
  [13:0] LINEAR_SLOPE — The slope of the linear which determine by the equation that Kn = 1/R, there, R is the ratio of the linear, which always is interger . The format is 8.24. (1:1)
0x288 AC_ADC_DRC_LKN — ADC DRC Linear Slope Low Setting Register
  [15:0] LINEAR_SLOPE — The slope of the linear which determine by the equation that Kn = 1/R, there, R is the ratio of the linear, which always is interger . The format is 8.24. (1:1)
0x28C AC_ADC_DRC_SFHAT reset 0x2 — ADC DRC Smooth filter Gain High Attack Time Coef Register
  fields as AC_DAC_DRC_SFHAT
0x290 AC_ADC_DRC_SFLAT reset 0x5600 — ADC DRC Smooth filter Gain Low Attack Time Coef Register
  fields as AC_DAC_DRC_SFLAT
0x294 AC_ADC_DRC_SFHRT — ADC DRC Smooth filter Gain High Release Time Coef Register
  fields as AC_DAC_DRC_SFHRT
0x298 AC_ADC_DRC_SFLRT reset 0xF04 — ADC DRC Smooth filter Gain Low Release Time Coef Register
  fields as AC_DAC_DRC_SFLRT
0x29C AC_ADC_DRC_MXGHS reset 0xFE56 — ADC DRC MAX Gain High Setting Register
  fields as AC_DAC_DRC_MXGHS
0x2A0 AC_ADC_DRC_MXGLS reset 0xCB0F — ADC DRC MIN Gain Low Setting Register
  fields as AC_DAC_DRC_MXGLS
0x2A8 AC_ADC_DRC_MNGLS reset 0x2C3F — ADC DRC MIN Gain High Setting Register
  fields as AC_DAC_DRC_MNGLS
0x2AC AC_ADC_DRC_EPSHC — ADC DRC Expander Smooth Time High Coef Register
  fields as AC_DAC_DRC_EPSHC
0x2B0 AC_ADC_DRC_EPSLC reset 0x640C — ADC DRC Expander Smooth Time Low Coef Register
  fields as AC_DAC_DRC_EPSLC
0x2B4 AC_ADC_DRC_OPT — ADC DRC Optimum Register
  [10] GAIN_SMOOTH_USE_THE_EXPANDER — The gain smooth use the expander coefficient when the energy in expander range 0 : Use the normal smooth coefficient 1 : Use the expander coefficient
  [9] GAIN_NORMAL_SMOOTH_COEFFICIENT_SELECTION — The gain normal smooth coefficient selection mode set 0 : Both release and attack coefficient use hysteresis 1 : Only the attack coefficient use hysteresis
  [8] MIN_OF_ENERGY_SET_IN — The min of energy set in peak detect mode 0 : -120dB 1 : -210dB
  [7] ENERGY_MODE_SELECT_IN_RMS — The energy mode select in rms detect mode 0 : The energy is RMS 1 : The energy is square of RMS
  [6] DRC_DATA_OUTPUT_WHEN_DRC — DRC data output when DRC disable and DRC delay data output complete. 0 : The output is the input music data 1 : The output is 0
  [5] DRC_GAIN_DEFAULT_VALUE — DRC gain default value setting 0: The default gain is 1 1: The default gain is 0
    0=The default gain is 1; 1=The default gain is 0
  [4:0] GAIN_SMOOTH_HYSTERESIS — The hysteresis of the gain smooth filter to use the decay time coefficient or the attack time coefficient. When in the decay time state, if g(n-1)-g(n)>hysteresis, then the state will change to attack time state, and when in the attack time, if g(n)-g(n-1)>hysteresis, then the state will change to decay time state. Note the hysteresis of 0x00 and 0x04 is the same. 00000: 2^(-20) 00001: 2^(-19) 00010: 2^(-18) ----------------- 10011: 2^(-1) 10100 ~11111: 1 hysteresis = 2^(n-20),except n=0x00, and n less 0x14.
    0=_2_circumflex__openingparen__minus_20_closingparen_ (2^(-20)); 1=_2_circumflex__openingparen__minus_19_closingparen_ (2^(-19)); 2=_2_circumflex__openingparen__minus_18_closingparen_ (2^(-18) -----------------); 19=_2_circumflex__openingparen__minus_1_closingparen_ (2^(-1) 10100 ~11111: 1 hysteresis = 2^(n-20),except n=0x00, and n less 0x14.)
0x300 AC_PR_CFG reset 0x10000000 — AC Parameter Configuration Register
  [28] ADDA_PR_RST — ADDA_PR Reset. 0: Assert 1: De-assert
    0=Assert; 1=deassert
  [24] ADDA_PR_RW — ADDA_PR Read or Write. 0: Read 1: Write
    0=Read; 1=Write
  [20:16] ADDA_PR_ADDR — ADDA_PR Address[4:0].
  [15:8] ADDA_PR_WDAT — ADDA_PR Write Data [7:0].
  [7:0] ADDA_PR_RDAT — ADDA_PR Read Data[7:0].
